# F28x7x_flash_ctrl_regs register map
Vendor: Texas Instruments
Peripheral module from a debugger description file (folder C2000).
Address unit: 16 bits
Registers are 32-bit, read-write, no defined reset value unless marked. A register's access mark holds for its fields unless they carry their own. Offsets are as the file gives them; lines under a group give offsets from that group; [hi:lo] are bit positions; {n}, {i} and the like mark numbered series; 'fields as' and 'values as' point back to an identical list; <NAME> marks a mode.

## FLASH_CTRL_REGS
0x00 FRDCNTL — Flash Read Control Register
  [11:8] RWAIT — Number of C28x clock in a RDCLK period
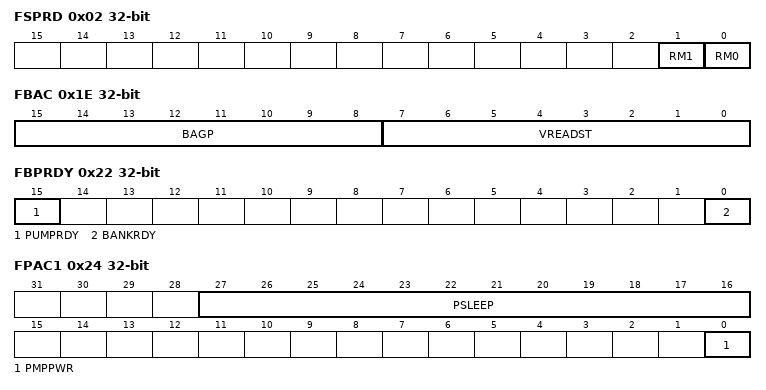
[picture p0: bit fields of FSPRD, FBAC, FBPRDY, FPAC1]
0x02 FSPRD — Flash Read Margin Control Register
  [1] RM1 — Readmargin1 Configuration
  [0] RM0 — ReadMargin0 Configuration
0x1E FBAC — Flash Bank Access Control Register
  [15:8] BAGP — Bank Active Grace Period
  [7:0] VREADST — VREAD Setup Time Count
0x20 FBFALLBACK — Flash Bank Fallback Power Register
  [1:0] BNKPWR0 — Bank Power Mode
0x22 FBPRDY — Flash Bank Pump Ready Register
  [15] PUMPRDY — Flash Pump Active Power Mode
  [0] BANKRDY — Flash Bank Active Power State
0x24 FPAC1 — Flash Pump Access Control Register 1
  [27:16] PSLEEP — Pump Sleep Down Count
  [0] PMPPWR — Charge Pump Fallback Power Mode
0x26 FPAC2 — Flash Pump Access Control Register 2
  [15:0] PAGP — Pump Active Grace Period
0x28 FMAC — Flash Module Access Control Register
  [2:0] BANK — Flash Bank for FSM and Software Interface Operations
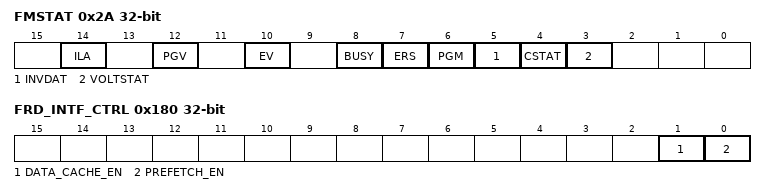
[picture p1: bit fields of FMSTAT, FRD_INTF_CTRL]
0x2A FMSTAT — Flash Module Status Register
  [14] ILA — Illegal Address Detected
  [12] PGV — Programming Verify Status
  [10] EV — Erase Verify Status
  [8] BUSY — Busy Bit
  [7] ERS — Erase Operation Status
  [6] PGM — Program Operation Status
  [5] INVDAT — Invalid Data
  [4] CSTAT — Command Fail Status
  [3] VOLTSTAT — Flash Pump Power Status
0x180 FRD_INTF_CTRL — Flash Read Interface Control Register
  [1] DATA_CACHE_EN — Data Cache Enable
  [0] PREFETCH_EN — Prefetch Enable
